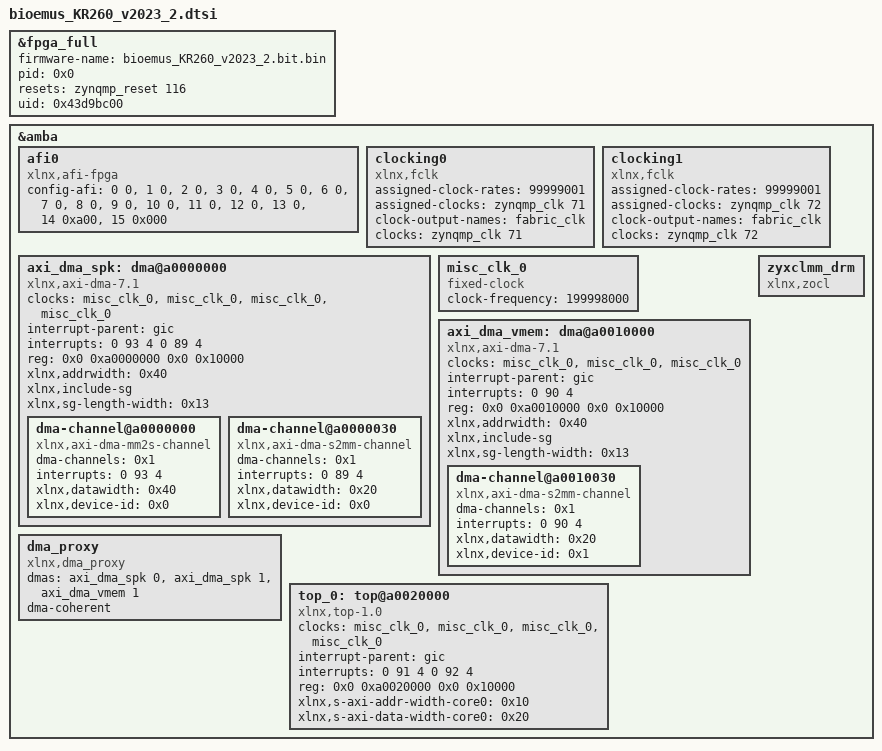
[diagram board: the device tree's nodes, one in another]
/*
 * CAUTION: This file is automatically generated by Xilinx.
 * Version: XSCT 2023.2
 * Today is: Thu Apr 18 13:26:56 2024
 */


/dts-v1/;
/plugin/;
/ {
	fragment@0 {
		target = <&fpga_full>;
		overlay0: __overlay__ {
			#address-cells = <2>;
			#size-cells = <2>;
			firmware-name = "bioemus_KR260_v2023_2.bit.bin";
			pid = <0x0>;
			resets = <&zynqmp_reset 116>;
			uid = <0x43d9bc00>;
		};
	};
	fragment@1 {
		target = <&amba>;
		overlay1: __overlay__ {
			afi0: afi0 {
				compatible = "xlnx,afi-fpga";
				config-afi = < 0 0>, <1 0>, <2 0>, <3 0>, <4 0>, <5 0>, <6 0>, <7 0>, <8 0>, <9 0>, <10 0>, <11 0>, <12 0>, <13 0>, <14 0xa00>, <15 0x000>;
			};
			clocking0: clocking0 {
				#clock-cells = <0>;
				assigned-clock-rates = <99999001>;
				assigned-clocks = <&zynqmp_clk 71>;
				clock-output-names = "fabric_clk";
				clocks = <&zynqmp_clk 71>;
				compatible = "xlnx,fclk";
			};
			clocking1: clocking1 {
				#clock-cells = <0>;
				assigned-clock-rates = <99999001>;
				assigned-clocks = <&zynqmp_clk 72>;
				clock-output-names = "fabric_clk";
				clocks = <&zynqmp_clk 72>;
				compatible = "xlnx,fclk";
			};
		};
	};
	fragment@2 {
		target = <&amba>;
		overlay2: __overlay__ {
			#address-cells = <2>;
			#size-cells = <2>;
			axi_dma_spk: dma@a0000000 {
				#dma-cells = <1>;
				clock-names = "m_axi_mm2s_aclk", "m_axi_s2mm_aclk", "m_axi_sg_aclk", "s_axi_lite_aclk";
				clocks = <&misc_clk_0>, <&misc_clk_0>, <&misc_clk_0>, <&misc_clk_0>;
				compatible = "xlnx,axi-dma-7.1", "xlnx,axi-dma-1.00.a";
				interrupt-names = "mm2s_introut", "s2mm_introut";
				interrupt-parent = <&gic>;
				interrupts = <0 93 4 0 89 4>;
				reg = <0x0 0xa0000000 0x0 0x10000>;
				xlnx,addrwidth = <0x40>;
				xlnx,include-sg ;
				xlnx,sg-length-width = <0x13>;
				dma-channel@a0000000 {
					compatible = "xlnx,axi-dma-mm2s-channel";
					dma-channels = <0x1>;
					interrupts = <0 93 4>;
					xlnx,datawidth = <0x40>;
					xlnx,device-id = <0x0>;
				};
				dma-channel@a0000030 {
					compatible = "xlnx,axi-dma-s2mm-channel";
					dma-channels = <0x1>;
					interrupts = <0 89 4>;
					xlnx,datawidth = <0x20>;
					xlnx,device-id = <0x0>;
				};
			};
			misc_clk_0: misc_clk_0 {
				#clock-cells = <0>;
				clock-frequency = <199998000>;
				compatible = "fixed-clock";
			};
			axi_dma_vmem: dma@a0010000 {
				#dma-cells = <1>;
				clock-names = "m_axi_s2mm_aclk", "m_axi_sg_aclk", "s_axi_lite_aclk";
				clocks = <&misc_clk_0>, <&misc_clk_0>, <&misc_clk_0>;
				compatible = "xlnx,axi-dma-7.1", "xlnx,axi-dma-1.00.a";
				interrupt-names = "s2mm_introut";
				interrupt-parent = <&gic>;
				interrupts = <0 90 4>;
				reg = <0x0 0xa0010000 0x0 0x10000>;
				xlnx,addrwidth = <0x40>;
				xlnx,include-sg ;
				xlnx,sg-length-width = <0x13>;
				dma-channel@a0010030 {
					compatible = "xlnx,axi-dma-s2mm-channel";
					dma-channels = <0x1>;
					interrupts = <0 90 4>;
					xlnx,datawidth = <0x20>;
					xlnx,device-id = <0x1>;
				};
			};
			dma_proxy {
				compatible ="xlnx,dma_proxy";
				dmas = <&axi_dma_spk 0 &axi_dma_spk 1 &axi_dma_vmem 1>;
				dma-names = "dma_proxy_tx_ext_stim", "dma_proxy_rx_spk", "dma_proxy_rx_vmem";
				dma-coherent;
			};
			top_0: top@a0020000 {
				/* This is a place holder node for a custom IP, user may need to update the entries */
				clock-names = "M_AXIS_SPK_ACLK", "M_AXIS_VMEM_ACLK", "S00_AXI_LITE_ACLK", "S_AXIS_STIM_ACLK";
				clocks = <&misc_clk_0>, <&misc_clk_0>, <&misc_clk_0>, <&misc_clk_0>;
				compatible = "xlnx,top-1.0";
				interrupt-names = "dma_spk_intr", "dma_vmem_intr";
				interrupt-parent = <&gic>;
				interrupts = <0 91 4 0 92 4>;
				reg = <0x0 0xa0020000 0x0 0x10000>;
				xlnx,s-axi-addr-width-core0 = <0x10>;
				xlnx,s-axi-data-width-core0 = <0x20>;
			};
			zyxclmm_drm {
				compatible = "xlnx,zocl";
			};
		};
	};
};
